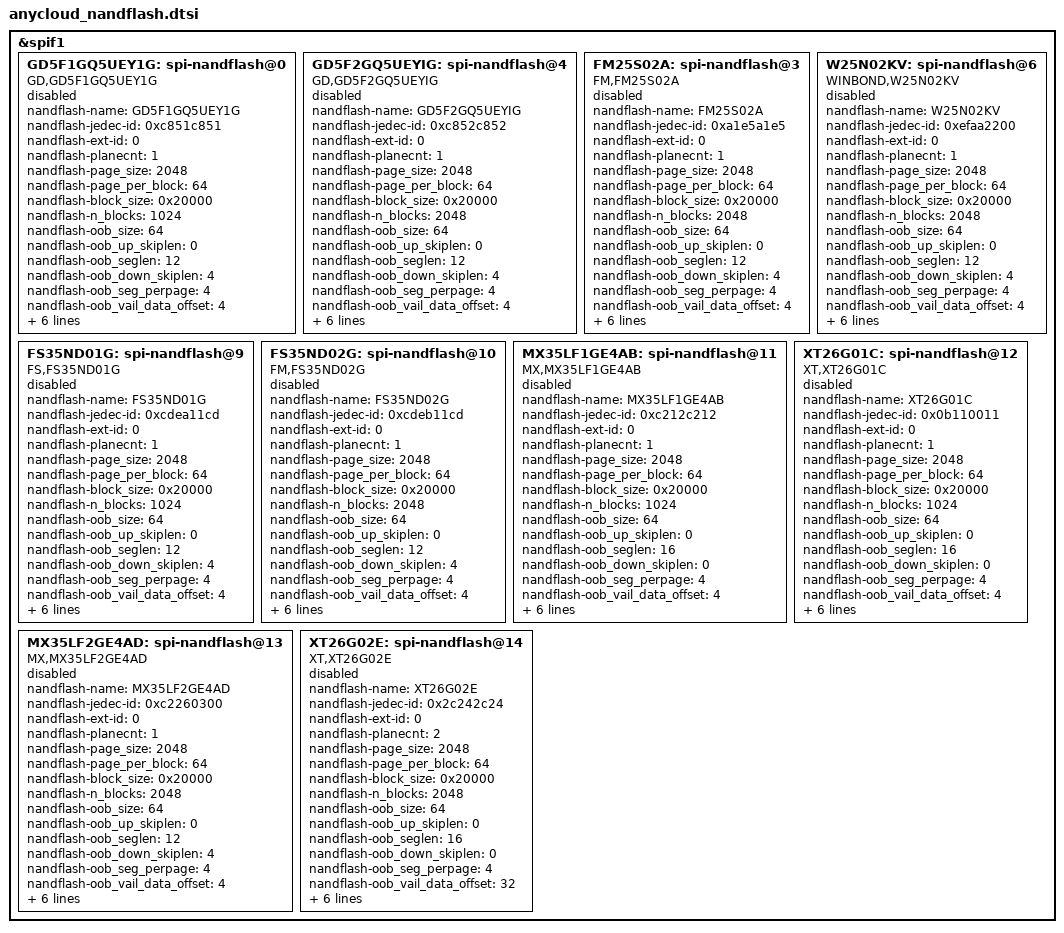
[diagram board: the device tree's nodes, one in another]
/*
 * Copyright (C) 2020 Anyka(Guangzhou) Microelectronics Technology Co., Ltd.
 *
 * Author: Zhang_zhipeng <zhang_zhipeng@anyka.com>
 *
 * This program is free software; you can redistribute it and/or modify
 * it under the terms of the GNU General Public License as published by
 * the Free Software Foundation; either version 2 of the License, or
 * (at your option) any later version.
 *
 * This program is distributed in the hope that it will be useful,
 * but WITHOUT ANY WARRANTY; without even the implied warranty of
 * MERCHANTABILITY or FITNESS FOR A PARTICULAR PURPOSE.  See the
 * GNU General Public License for more details.
 */

&spif1 {
	GD5F1GQ5UEY1G: spi-nandflash@0 {
		compatible = "GD,GD5F1GQ5UEY1G";
		nandflash-name = "GD5F1GQ5UEY1G";

		/* spiflash GD5F1GQ5UEY1G */
		nandflash-jedec-id = <0xc851c851>;
		nandflash-ext-id = <0>;
		nandflash-planecnt = <1>;
		nandflash-page_size = <2048>;
		nandflash-page_per_block = <64>;
		nandflash-block_size = <0x20000>;
		nandflash-n_blocks = <1024>;
		nandflash-oob_size = <64>;
		nandflash-oob_up_skiplen = <0>;
		nandflash-oob_seglen = <12>;
		nandflash-oob_down_skiplen = <4>;
		nandflash-oob_seg_perpage = <4>;
		nandflash-oob_vail_data_offset = <4>;

		/*
		* flags = SFLAG_DUAL_READ|SFLAG_QUAD_READ|SFLAG_QUAD_WRITE
		* = 0x8A0
		*/
		nandflash-flags = <0x8A0>;

		nandflash-b_wip = <0>;

		nandflash-b_qe = <8>;

		/* bad block flag ops */
		nandflash-badflag_offs = <0>;
		nandflash-badflag_len = <1>;

		/*
		 * 0x00000000:scan first one page
		 * 0x00008000:scan first two page
		 * 0x00010000:scan last  one page
		 * 0x00018000:scan last  two page
		 * 0x01000000:scan first and last page
		 */
		nandflash-badflag_option = <0x01000000>;

		status = "disable";
	};

	GD5F2GQ5UEYIG: spi-nandflash@4 {
		compatible = "GD,GD5F2GQ5UEYIG";
		nandflash-name = "GD5F2GQ5UEYIG";

		/* spiflash GD5F2GQ5UEYIG */
		nandflash-jedec-id = <0xc852c852>;
		nandflash-ext-id = <0>;
		nandflash-planecnt = <1>;
		nandflash-page_size = <2048>;
		nandflash-page_per_block = <64>;
		nandflash-block_size = <0x20000>;
		nandflash-n_blocks = <2048>;
		nandflash-oob_size = <64>;
		nandflash-oob_up_skiplen = <0>;
		nandflash-oob_seglen = <12>;
		nandflash-oob_down_skiplen = <4>;
		nandflash-oob_seg_perpage = <4>;
		nandflash-oob_vail_data_offset = <4>;

		/*
		* flags = SFLAG_DUAL_READ|SFLAG_QUAD_READ|SFLAG_QUAD_WRITE
		* = 0x8A0
		*/
		nandflash-flags = <0x8A0>;

		/* status reg bit map */
		nandflash-b_wip = <0>;

		nandflash-b_qe = <8>;

		/* bad block flag ops */
		nandflash-badflag_offs = <0>;
		nandflash-badflag_len = <1>;

		/*
		 * 0x00000000:scan first one page
		 * 0x00008000:scan first two page
		 * 0x00010000:scan last  one page
		 * 0x00018000:scan last  two page
		 * 0x01000000:scan first and last page
		 */
		nandflash-badflag_option = <0x01000000>;

		status = "disable";
	};

	FM25S02A: spi-nandflash@3 {
		compatible = "FM,FM25S02A";
		nandflash-name = "FM25S02A";

		/* spiflash FM25S02A */
		nandflash-jedec-id = <0xa1e5a1e5>;
		nandflash-ext-id = <0>;
		nandflash-planecnt = <1>;
		nandflash-page_size = <2048>;
		nandflash-page_per_block = <64>;
		nandflash-block_size = <0x20000>;
		nandflash-n_blocks = <2048>;
		nandflash-oob_size = <64>;
		nandflash-oob_up_skiplen = <0>;
		nandflash-oob_seglen = <12>;
		nandflash-oob_down_skiplen = <4>;
		nandflash-oob_seg_perpage = <4>;
		nandflash-oob_vail_data_offset = <4>;

		/*
		* flags = SFLAG_DUAL_READ|SFLAG_QUAD_READ|SFLAG_QUAD_WRITE
		* = 0x8A0
		*/
		nandflash-flags = <0x8A0>;

		/* status reg bit map */
		nandflash-b_wip = <0>;

		nandflash-b_qe = <8>;

		/* bad block flag ops */
		nandflash-badflag_offs = <0>;
		nandflash-badflag_len = <1>;

		/*
		 * 0x00000000:scan first one page
		 * 0x00008000:scan first two page
		 * 0x00010000:scan last  one page
		 * 0x00018000:scan last  two page
		 * 0x01000000:scan first and last page
		 */
		nandflash-badflag_option = <0x01000000>;

		status = "disable";
	};

	W25N02KV: spi-nandflash@6 {
		compatible = "WINBOND,W25N02KV";
		nandflash-name = "W25N02KV";

		/* spiflash W25N02KV */
		nandflash-jedec-id = <0xefaa2200>;
		nandflash-ext-id = <0>;
		nandflash-planecnt = <1>;
		nandflash-page_size = <2048>;
		nandflash-page_per_block = <64>;
		nandflash-block_size = <0x20000>;
		nandflash-n_blocks = <2048>;
		nandflash-oob_size = <64>;
		nandflash-oob_up_skiplen = <0>;
		nandflash-oob_seglen = <12>;
		nandflash-oob_down_skiplen = <4>;
		nandflash-oob_seg_perpage = <4>;
		nandflash-oob_vail_data_offset = <4>;

		/*
		* flags = SFLAG_DUAL_READ|SFLAG_QUAD_READ|SFLAG_QUAD_WRITE
		* = 0x8A0
		*/
		nandflash-flags = <0x8A0>;

		/* status reg bit map */
		nandflash-b_wip = <0>;

		nandflash-b_qe = <8>;

		/* bad block flag ops */
		nandflash-badflag_offs = <0>;
		nandflash-badflag_len = <1>;

		/*
		 * 0x00000000:scan first one page
		 * 0x00008000:scan first two page
		 * 0x00010000:scan last  one page
		 * 0x00018000:scan last  two page
		 * 0x01000000:scan first and last page
		 */
		nandflash-badflag_option = <0x01000000>;

		status = "disable";
	};

	FS35ND01G: spi-nandflash@9 {
		compatible = "FS,FS35ND01G";
		nandflash-name = "FS35ND01G";

		/* spiflash FS35ND01G */
		nandflash-jedec-id = <0xcdea11cd>;
		nandflash-ext-id = <0>;
		nandflash-planecnt = <1>;
		nandflash-page_size = <2048>;
		nandflash-page_per_block = <64>;
		nandflash-block_size = <0x20000>;
		nandflash-n_blocks = <1024>;
		nandflash-oob_size = <64>;
		nandflash-oob_up_skiplen = <0>;
		nandflash-oob_seglen = <12>;
		nandflash-oob_down_skiplen = <4>;
		nandflash-oob_seg_perpage = <4>;
		nandflash-oob_vail_data_offset = <4>;

		/*
		* flags = SFLAG_DUAL_READ|SFLAG_QUAD_READ|SFLAG_QUAD_WRITE
		* = 0x8A0
		*/
		nandflash-flags = <0x8A0>;

		/* status reg bit map */
		nandflash-b_wip = <0>;

		nandflash-b_qe = <8>;

		/* bad block flag ops */
		nandflash-badflag_offs = <0>;
		nandflash-badflag_len = <1>;

		/*
		 * 0x00000000:scan first one page
		 * 0x00008000:scan first two page
		 * 0x00010000:scan last  one page
		 * 0x00018000:scan last  two page
		 * 0x01000000:scan first and last page
		 */
		nandflash-badflag_option = <0x01000000>;

		status = "disable";
	};

	FS35ND02G: spi-nandflash@10 {
		compatible = "FM,FS35ND02G";
		nandflash-name = "FS35ND02G";

		/* spiflash FS35ND02G */
		nandflash-jedec-id = <0xcdeb11cd>;
		nandflash-ext-id = <0>;
		nandflash-planecnt = <1>;
		nandflash-page_size = <2048>;
		nandflash-page_per_block = <64>;
		nandflash-block_size = <0x20000>;
		nandflash-n_blocks = <2048>;
		nandflash-oob_size = <64>;
		nandflash-oob_up_skiplen = <0>;
		nandflash-oob_seglen = <12>;
		nandflash-oob_down_skiplen = <4>;
		nandflash-oob_seg_perpage = <4>;
		nandflash-oob_vail_data_offset = <4>;

		/*
		* flags = SFLAG_DUAL_READ|SFLAG_QUAD_READ|SFLAG_QUAD_WRITE
		* = 0x8A0
		*/
		nandflash-flags = <0x8A0>;

		/* status reg bit map */
		nandflash-b_wip = <0>;

		nandflash-b_qe = <8>;

		/* bad block flag ops */
		nandflash-badflag_offs = <0>;
		nandflash-badflag_len = <1>;

		/*
		 * 0x00000000:scan first one page
		 * 0x00008000:scan first two page
		 * 0x00010000:scan last  one page
		 * 0x00018000:scan last  two page
		 * 0x01000000:scan first and last page
		 */
		nandflash-badflag_option = <0x01000000>;

		status = "disable";
	};

	MX35LF1GE4AB: spi-nandflash@11 {
		compatible = "MX,MX35LF1GE4AB";
		nandflash-name = "MX35LF1GE4AB";

		/* spiflash MX35LF1GE4AB*/
		nandflash-jedec-id = <0xc212c212>;
		nandflash-ext-id = <0>;
		nandflash-planecnt = <1>;
		nandflash-page_size = <2048>;
		nandflash-page_per_block = <64>;
		nandflash-block_size = <0x20000>;
		nandflash-n_blocks = <1024>;
		nandflash-oob_size = <64>;
		nandflash-oob_up_skiplen = <0>;
		nandflash-oob_seglen = <16>;
		nandflash-oob_down_skiplen = <0>;
		nandflash-oob_seg_perpage = <4>;
		nandflash-oob_vail_data_offset = <4>;

		/*
		* flags = SFLAG_DUAL_READ|SFLAG_QUAD_READ|SFLAG_QUAD_WRITE
		* = 0x8A0
		*/
		nandflash-flags = <0x8A0>;

		/* status reg bit map */
		nandflash-b_wip = <0>;

		nandflash-b_qe = <8>;

		/* bad block flag ops */
		nandflash-badflag_offs = <0>;
		nandflash-badflag_len = <1>;

		/*
		 * 0x00000000:scan first one page
		 * 0x00008000:scan first two page
		 * 0x00010000:scan last  one page
		 * 0x00018000:scan last  two page
		 * 0x01000000:scan first and last page
		 */
		nandflash-badflag_option = <0x00008000>;

		status = "disable";
	};

    XT26G01C: spi-nandflash@12 {
		compatible = "XT,XT26G01C";
		nandflash-name = "XT26G01C";

		/* spiflash XT26G01C */
		nandflash-jedec-id = <0x0b110011>;
		nandflash-ext-id = <0>;
		nandflash-planecnt = <1>;
		nandflash-page_size = <2048>;
		nandflash-page_per_block = <64>;
		nandflash-block_size = <0x20000>;
		nandflash-n_blocks = <1024>;
		nandflash-oob_size = <64>;
		nandflash-oob_up_skiplen = <0>;
		nandflash-oob_seglen = <16>;
		nandflash-oob_down_skiplen = <0>;
		nandflash-oob_seg_perpage = <4>;
		nandflash-oob_vail_data_offset = <4>;

		/*
		* flags = SFLAG_DUAL_READ|SFLAG_QUAD_READ|SFLAG_QUAD_WRITE
		* = 0x8A0
		*/
		nandflash-flags = <0x8A0>;

		/* status reg bit map */
		nandflash-b_wip = <0>;

		nandflash-b_qe = <8>;

		/* bad block flag ops */
		nandflash-badflag_offs = <0>;
		nandflash-badflag_len = <1>;

		/*
		 * 0x00000000:scan first one page
		 * 0x00008000:scan first two page
		 * 0x00010000:scan last  one page
		 * 0x00018000:scan last  two page
		 * 0x01000000:scan first and last page
		 */
		nandflash-badflag_option = <0x00000000>;

		status = "disable";
    };

    MX35LF2GE4AD: spi-nandflash@13 {
		compatible = "MX,MX35LF2GE4AD";
		nandflash-name = "MX35LF2GE4AD";

		/* spiflash MX35LF2GE4AD */
		nandflash-jedec-id = <0xc2260300>;
		nandflash-ext-id = <0>;
		nandflash-planecnt = <1>;
		nandflash-page_size = <2048>;
		nandflash-page_per_block = <64>;
		nandflash-block_size = <0x20000>;
		nandflash-n_blocks = <2048>;
		nandflash-oob_size = <64>;
		nandflash-oob_up_skiplen = <0>;
		nandflash-oob_seglen = <12>;
		nandflash-oob_down_skiplen = <4>;
		nandflash-oob_seg_perpage = <4>;
		nandflash-oob_vail_data_offset = <4>;

		/*
		* flags = SFLAG_DUAL_READ|SFLAG_QUAD_READ|SFLAG_QUAD_WRITE
		* = 0x8A0
		*/
		nandflash-flags = <0x8A0>;

		/* status reg bit map */
		nandflash-b_wip = <0>;
		nandflash-b_qe = <8>;

		/* bad block flag ops */
		nandflash-badflag_offs = <0>;
		nandflash-badflag_len = <1>;

		/*
		 * 0x00000000:scan first one page
		 * 0x00008000:scan first two page
		 * 0x00010000:scan last  one page
		 * 0x00018000:scan last  two page
		 * 0x01000000:scan first and last page
		 */
		nandflash-badflag_option = <0x00008000>;

		status = "disable";
    };

	XT26G02E: spi-nandflash@14 { 
		compatible = "XT,XT26G02E";
		nandflash-name = "XT26G02E";
		
		/* spiflash XT26G02E */
		nandflash-jedec-id = <0x2c242c24>; 
		nandflash-ext-id = <0>;
		nandflash-planecnt = <2>;
		nandflash-page_size = <2048>;
		nandflash-page_per_block = <64>;
		nandflash-block_size = <0x20000>;
		nandflash-n_blocks = <2048>;
		nandflash-oob_size = <64>;		  
		nandflash-oob_up_skiplen = <0>;
		nandflash-oob_seglen = <16>;
		nandflash-oob_down_skiplen = <0>;	
		nandflash-oob_seg_perpage = <4>;
		nandflash-oob_vail_data_offset = <32>;

		/*
		* flags = SFLAG_DUAL_READ|SFLAG_QUAD_READ|SFLAG_QUAD_WRITE|SFLAG_QUAD_NO_QE
		* = 0x48A0
		*/
		nandflash-flags = <0x48A0>;

		nandflash-b_wip = <0>;		

		nandflash-b_qe = <8>; 	

		/* bad block flag ops */
		nandflash-badflag_offs = <0>;
		nandflash-badflag_len = <1>;

		/*
		 * 0x00000000:scan first one page
		 * 0x00008000:scan first two page
		 * 0x00010000:scan last  one page
		 * 0x00018000:scan last  two page
		 * 0x01000000:scan first and last page
		 */
		nandflash-badflag_option = <0x00000000>;	
		
		status = "disable";
	};

};




